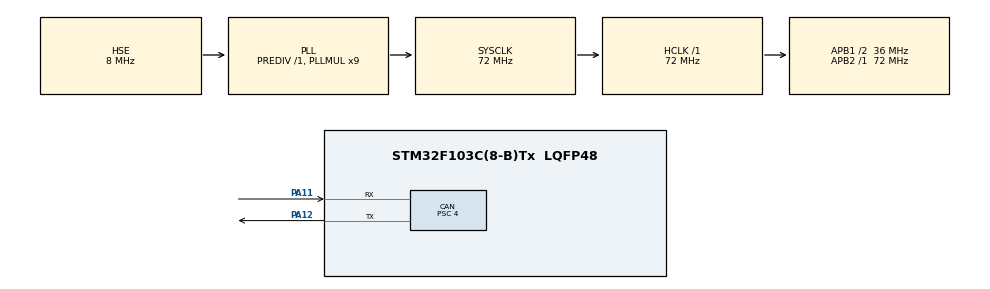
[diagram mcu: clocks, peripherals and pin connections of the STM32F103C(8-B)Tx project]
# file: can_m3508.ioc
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CAN.ABOM=DISABLE
CAN.BS1=CAN_BS1_4TQ
CAN.BS2=CAN_BS2_4TQ
CAN.CalculateBaudRate=1000000
CAN.CalculateTimeBit=1000
CAN.CalculateTimeQuantum=111.11111111111111
CAN.NART=ENABLE
CAN.Prescaler=4
CAN.TXFP=DISABLE
Mcu.Family=STM32F1
Mcu.Name=STM32F103C(8-B)Tx
Mcu.Package=LQFP48
NVIC.PriorityGroup=NVIC_PRIORITYGROUP_4
NVIC.USB_LP_CAN1_RX0_IRQn=true\:0\:0\:false\:false\:true\:true\:true\:true
PA11.Mode=CAN_Activate
PA11.Signal=CAN_RX
PA12.Mode=CAN_Activate
PA12.Signal=CAN_TX
PA13.Mode=Serial_Wire
PA13.Signal=SYS_JTMS-SWDIO
PA14.Mode=Serial_Wire
PA14.Signal=SYS_JTCK-SWCLK
PD0-OSC_IN.Mode=HSE-External-Oscillator
PD0-OSC_IN.Signal=RCC_OSC_IN
PD1-OSC_OUT.Mode=HSE-External-Oscillator
PD1-OSC_OUT.Signal=RCC_OSC_OUT
ProjectManager.HeapSize=0x200
ProjectManager.StackSize=0x400
ProjectManager.TargetToolchain=MDK-ARM V5
RCC.AHBFreq_Value=72000000
RCC.APB1CLKDivider=RCC_HCLK_DIV2
RCC.APB1Freq_Value=36000000
RCC.APB1TimFreq_Value=72000000
RCC.APB2Freq_Value=72000000
RCC.APB2TimFreq_Value=72000000
RCC.HCLKFreq_Value=72000000
RCC.PLLMUL=RCC_PLL_MUL9
RCC.PLLSourceVirtual=RCC_PLLSOURCE_HSE
RCC.SYSCLKFreq_VALUE=72000000
RCC.SYSCLKSource=RCC_SYSCLKSOURCE_PLLCLK
RCC.USBFreq_Value=72000000
board=custom

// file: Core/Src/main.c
/* USER CODE BEGIN Header */
/**
 ******************************************************************************
 * @file           : main.c
 * @brief          : Main program body
 ******************************************************************************
 * @attention
 *
 * Copyright (c) 2023 STMicroelectronics.
 * All rights reserved.
 *
 * This software is licensed under terms that can be found in the LICENSE file
 * in the root directory of this software component.
 * If no LICENSE file comes with this software, it is provided AS-IS.
 *
 ******************************************************************************
 */
/* USER CODE END Header */
#include "main.h"
#include "can.h"
#include "gpio.h"

/* USER CODE BEGIN Includes */
#include "pid.h"
#include "motor.h"
/* USER CODE END Includes */

/* USER CODE BEGIN PV */
int torque;
float setspeed = 1000;
float kp = 5;
float ki = 0.8;
float kd = 0;
float set_round = 3; //设置圈数
float actual_round;
float angle_setspeed_ ;
/* USER CODE END PV */

void SystemClock_Config(void);

int main(void)
{
  /* USER CODE BEGIN 1 */

  // float real_total_angle;
  // float angle_setspeed;
  // float set_angle;
  //  u8 key;
  //  s8 key_cnt;
  u8 i=0;

  /* USER CODE END 1 */

  /* MCU Configuration--------------------------------------------------------*/

  /* Reset of all peripherals, Initializes the Flash interface and the Systick. */
  HAL_Init();

  /* Configure the system clock */
  SystemClock_Config();

  /* Initialize all configured peripherals */
  MX_GPIO_Init();
  MX_CAN_Init();
  /* USER CODE BEGIN 2 */

  // CAN过滤器初始化
  can_filter_init();

  // PID参数初始化
  pid_init(&pid_angle, 1500,0, 5, 0,5.0f, 0.0f, 0.0f);
  pid_init(&pid_motor, 5000, 3000, 0, 0,5.0f, 0.8f, 0.0f);

  /* USER CODE END 2 */

  /* Infinite loop */
  /* USER CODE BEGIN WHILE */
  while (1)
  {
    //角速度计算
    angle_setspeed_ = angle_speed_cacl(set_round);
    // PID 电流力矩计算
    torque = pid_calc(&pid_motor, (float)moto_chassis[i].speed_rpm, angle_setspeed_);
    // CAN发送
    can_cmd_send(torque);
    //采样时间
    HAL_Delay(10);

    //实际位置
    actual_round=(float)moto_chassis[i].total_angle / 8192.0f * 187.0f  / 3591.0f;//1.0f/36.0f
    // PID参数重设
    pid_reset(&pid_motor, kp, ki, kd);
    //  HAL_CAN_Start(&hcan);
    // HAL_CAN_ActivateNotification(&hcan, CAN_IT_RX_FIFO0_MSG_PENDING);
    //  can_cmd_send(torque);
    /* USER CODE END WHILE */

  }
}

void SystemClock_Config(void)
{
  RCC_OscInitTypeDef RCC_OscInitStruct = {0};
  RCC_ClkInitTypeDef RCC_ClkInitStruct = {0};

  /** Initializes the RCC Oscillators according to the specified parameters
   * in the RCC_OscInitTypeDef structure.
   */
  RCC_OscInitStruct.OscillatorType = RCC_OSCILLATORTYPE_HSE;
  RCC_OscInitStruct.HSEState = RCC_HSE_ON;
  RCC_OscInitStruct.HSEPredivValue = RCC_HSE_PREDIV_DIV1;
  RCC_OscInitStruct.HSIState = RCC_HSI_ON;
  RCC_OscInitStruct.PLL.PLLState = RCC_PLL_ON;
  RCC_OscInitStruct.PLL.PLLSource = RCC_PLLSOURCE_HSE;
  RCC_OscInitStruct.PLL.PLLMUL = RCC_PLL_MUL9;
  if (HAL_RCC_OscConfig(&RCC_OscInitStruct) != HAL_OK)
  {
    Error_Handler();
  }

  /** Initializes the CPU, AHB and APB buses clocks
   */
  RCC_ClkInitStruct.ClockType = RCC_CLOCKTYPE_HCLK | RCC_CLOCKTYPE_SYSCLK | RCC_CLOCKTYPE_PCLK1 | RCC_CLOCKTYPE_PCLK2;
  RCC_ClkInitStruct.SYSCLKSource = RCC_SYSCLKSOURCE_PLLCLK;
  RCC_ClkInitStruct.AHBCLKDivider = RCC_SYSCLK_DIV1;
  RCC_ClkInitStruct.APB1CLKDivider = RCC_HCLK_DIV2;
  RCC_ClkInitStruct.APB2CLKDivider = RCC_HCLK_DIV1;

  if (HAL_RCC_ClockConfig(&RCC_ClkInitStruct, FLASH_LATENCY_2) != HAL_OK)
  {
    Error_Handler();
  }
}

void Error_Handler(void)
{
  __disable_irq();
  while (1)
  {
  }
}
